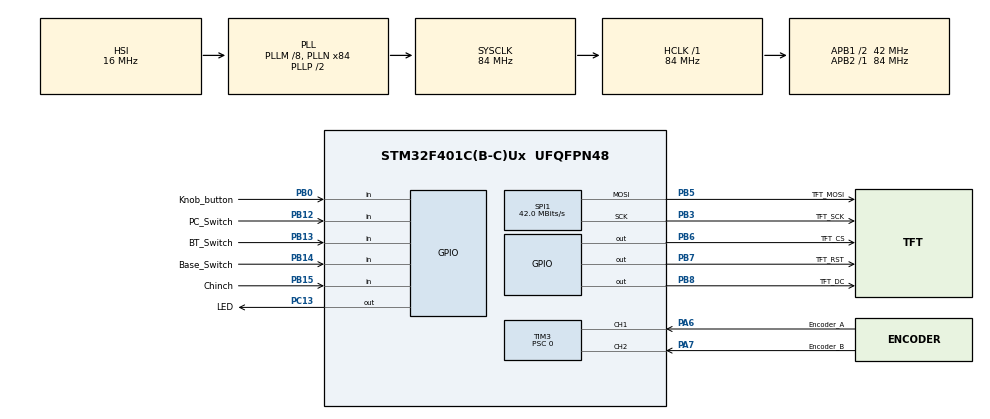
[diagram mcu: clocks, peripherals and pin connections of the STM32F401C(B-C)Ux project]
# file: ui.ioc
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Dma.Request0=SPI1_TX
Dma.SPI1_TX.0.Direction=DMA_MEMORY_TO_PERIPH
Dma.SPI1_TX.0.FIFOMode=DMA_FIFOMODE_DISABLE
Dma.SPI1_TX.0.Instance=DMA2_Stream3
Dma.SPI1_TX.0.MemDataAlignment=DMA_MDATAALIGN_BYTE
Dma.SPI1_TX.0.MemInc=DMA_MINC_ENABLE
Dma.SPI1_TX.0.Mode=DMA_NORMAL
Dma.SPI1_TX.0.PeriphDataAlignment=DMA_PDATAALIGN_BYTE
Dma.SPI1_TX.0.PeriphInc=DMA_PINC_DISABLE
Dma.SPI1_TX.0.Priority=DMA_PRIORITY_LOW
Mcu.Family=STM32F4
Mcu.Name=STM32F401C(B-C)Ux
Mcu.Package=UFQFPN48
NVIC.DMA2_Stream3_IRQn=true\:0\:0\:false\:false\:true\:false\:true\:true
NVIC.PriorityGroup=NVIC_PRIORITYGROUP_4
NVIC.TIM1_UP_TIM10_IRQn=true\:0\:0\:false\:false\:true\:true\:true\:true
PA6.GPIO_Label=Encoder_A
PA6.GPIO_Speed=GPIO_SPEED_FREQ_VERY_HIGH
PA6.Signal=S_TIM3_CH1
PA7.GPIO_Label=Encoder_B
PA7.GPIO_Speed=GPIO_SPEED_FREQ_VERY_HIGH
PA7.Signal=S_TIM3_CH2
PB0.GPIO_Label=Knob_button
PB0.GPIO_PuPd=GPIO_PULLUP
PB0.Signal=GPIO_Input
PB12.GPIO_Label=PC_Switch
PB12.GPIO_Mode=GPIO_MODE_INPUT
PB12.GPIO_PuPd=GPIO_NOPULL
PB12.Signal=GPIO_Input
PB13.GPIO_Label=BT_Switch
PB13.GPIO_Mode=GPIO_MODE_INPUT
PB13.GPIO_PuPd=GPIO_NOPULL
PB13.Signal=GPIO_Input
PB14.GPIO_Label=Base_Switch
PB14.GPIO_Mode=GPIO_MODE_INPUT
PB14.GPIO_PuPd=GPIO_NOPULL
PB14.Signal=GPIO_Input
PB15.GPIO_Label=Chinch
PB15.GPIO_PuPd=GPIO_PULLDOWN
PB15.Signal=GPIO_Input
PB3.GPIO_Label=TFT_SCK
PB3.GPIO_PuPd=GPIO_PULLDOWN
PB3.Mode=TX_Only_Simplex_Unidirect_Master
PB3.Signal=SPI1_SCK
PB5.GPIO_Label=TFT_MOSI
PB5.Mode=TX_Only_Simplex_Unidirect_Master
PB5.Signal=SPI1_MOSI
PB6.GPIO_Label=TFT_CS
PB6.GPIO_PuPd=GPIO_PULLUP
PB6.GPIO_Speed=GPIO_SPEED_FREQ_VERY_HIGH
PB6.PinState=GPIO_PIN_SET
PB6.Signal=GPIO_Output
PB7.GPIO_Label=TFT_RST
PB7.GPIO_PuPd=GPIO_PULLUP
PB7.GPIO_Speed=GPIO_SPEED_FREQ_VERY_HIGH
PB7.PinState=GPIO_PIN_SET
PB7.Signal=GPIO_Output
PB8.GPIO_Label=TFT_DC
PB8.GPIO_PuPd=GPIO_PULLUP
PB8.GPIO_Speed=GPIO_SPEED_FREQ_VERY_HIGH
PB8.PinState=GPIO_PIN_SET
PB8.Signal=GPIO_Output
PC13-ANTI_TAMP.GPIO_Label=LED
PC13-ANTI_TAMP.Signal=GPIO_Output
ProjectManager.HeapSize=0x200
ProjectManager.StackSize=0x400
ProjectManager.TargetToolchain=STM32CubeIDE
RCC.48MHZClocksFreq_Value=42000000
RCC.AHBFreq_Value=84000000
RCC.APB1CLKDivider=RCC_HCLK_DIV2
RCC.APB1Freq_Value=42000000
RCC.APB1TimFreq_Value=84000000
RCC.APB2Freq_Value=84000000
RCC.APB2TimFreq_Value=84000000
RCC.CortexFreq_Value=84000000
RCC.HCLKFreq_Value=84000000
RCC.HSE_VALUE=25000000
RCC.HSI_VALUE=16000000
RCC.LSE_VALUE=32768
RCC.PLLM=8
RCC.PLLN=84
RCC.SYSCLKFreq_VALUE=84000000
RCC.SYSCLKSource=RCC_SYSCLKSOURCE_PLLCLK
RCC.VCOOutputFreq_Value=168000000
SH.S_TIM3_CH1.0=TIM3_CH1,Encoder_Interface
SH.S_TIM3_CH2.0=TIM3_CH2,Encoder_Interface
SPI1.BaudRatePrescaler=SPI_BAUDRATEPRESCALER_2
SPI1.CalculateBaudRate=42.0 MBits/s
SPI1.Direction=SPI_DIRECTION_2LINES
SPI1.Mode=SPI_MODE_MASTER
SPI1.VirtualType=VM_MASTER
TIM10.Period=1000-1
TIM10.Prescaler=84-1
TIM3.EncoderMode=TIM_ENCODERMODE_TI12
TIM3.Prescaler=0
VP_TIM10_VS_ClockSourceINT.Mode=Enable_Timer
board=custom

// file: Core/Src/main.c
/* USER CODE BEGIN Header */
/**
 ******************************************************************************
 * @file           : main.c
 * @brief          : Main program body
 ******************************************************************************
 * @attention
 *
 * Copyright (c) 2026 STMicroelectronics.
 * All rights reserved.
 *
 * This software is licensed under terms that can be found in the LICENSE file
 * in the root directory of this software component.
 * If no LICENSE file comes with this software, it is provided AS-IS.
 *
 ******************************************************************************
 */
/* USER CODE END Header */
#include "main.h"
#include "dma.h"
#include "spi.h"
#include "tim.h"
#include "gpio.h"

/* USER CODE BEGIN PV */
static volatile uint8_t display_refresh_ = 0;
/* USER CODE END PV */

void SystemClock_Config(void);

int main(void) {

	/* MCU Configuration--------------------------------------------------------*/

	/* Reset of all peripherals, Initializes the Flash interface and the Systick. */
	HAL_Init();

	/* Configure the system clock */
	SystemClock_Config();

	/* Initialize all configured peripherals */
	MX_GPIO_Init();
	MX_DMA_Init();
	MX_TIM10_Init();
	MX_TIM3_Init();
	MX_SPI1_Init();
	/* USER CODE BEGIN 2 */
	time_init();
	knob_init();

	ST7789_Init();
	ui_init();
	/* USER CODE END 2 */

	/* Infinite loop */
	while (1) {

		/* USER CODE BEGIN 3 */
		if (display_refresh_) {
			display_refresh_ = 0;
			ui_init();
		}
		ui_update();
	}
	/* USER CODE END 3 */
}

void SystemClock_Config(void) {
	RCC_OscInitTypeDef RCC_OscInitStruct = { 0 };
	RCC_ClkInitTypeDef RCC_ClkInitStruct = { 0 };

	/** Configure the main internal regulator output voltage
	 */
	__HAL_RCC_PWR_CLK_ENABLE();
	__HAL_PWR_VOLTAGESCALING_CONFIG(PWR_REGULATOR_VOLTAGE_SCALE2);

	/** Initializes the RCC Oscillators according to the specified parameters
	 * in the RCC_OscInitTypeDef structure.
	 */
	RCC_OscInitStruct.OscillatorType = RCC_OSCILLATORTYPE_HSI;
	RCC_OscInitStruct.HSIState = RCC_HSI_ON;
	RCC_OscInitStruct.HSICalibrationValue = RCC_HSICALIBRATION_DEFAULT;
	RCC_OscInitStruct.PLL.PLLState = RCC_PLL_ON;
	RCC_OscInitStruct.PLL.PLLSource = RCC_PLLSOURCE_HSI;
	RCC_OscInitStruct.PLL.PLLM = 8;
	RCC_OscInitStruct.PLL.PLLN = 84;
	RCC_OscInitStruct.PLL.PLLP = RCC_PLLP_DIV2;
	RCC_OscInitStruct.PLL.PLLQ = 4;
	if (HAL_RCC_OscConfig(&RCC_OscInitStruct) != HAL_OK) {
		Error_Handler();
	}

	/** Initializes the CPU, AHB and APB buses clocks
	 */
	RCC_ClkInitStruct.ClockType = RCC_CLOCKTYPE_HCLK | RCC_CLOCKTYPE_SYSCLK
			| RCC_CLOCKTYPE_PCLK1 | RCC_CLOCKTYPE_PCLK2;
	RCC_ClkInitStruct.SYSCLKSource = RCC_SYSCLKSOURCE_PLLCLK;
	RCC_ClkInitStruct.AHBCLKDivider = RCC_SYSCLK_DIV1;
	RCC_ClkInitStruct.APB1CLKDivider = RCC_HCLK_DIV2;
	RCC_ClkInitStruct.APB2CLKDivider = RCC_HCLK_DIV1;

	if (HAL_RCC_ClockConfig(&RCC_ClkInitStruct, FLASH_LATENCY_2) != HAL_OK) {
		Error_Handler();
	}
}

void Error_Handler(void) {
	__disable_irq();
	while (1) {
	}
}
